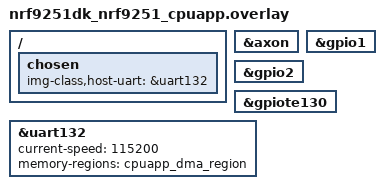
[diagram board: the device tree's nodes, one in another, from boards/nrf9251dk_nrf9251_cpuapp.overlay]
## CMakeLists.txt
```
#
# Copyright (c) 2026 Nordic Semiconductor ASA
#
# SPDX-License-Identifier: LicenseRef-Nordic-5-Clause
#

cmake_minimum_required(VERSION 3.20.0)

find_package(Zephyr REQUIRED HINTS $ENV{ZEPHYR_BASE})
project(wildfire_classification)

target_sources(app PRIVATE
  src/main.c
  src/classification.c
  src/host_input.c
)
```

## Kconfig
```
#
# Copyright (c) 2026 Nordic Semiconductor ASA
#
# SPDX-License-Identifier: LicenseRef-Nordic-5-Clause
#

menu "Wildfire classification application"

config WILDFIRE_SCORE_THRESHOLD
	int "Fire LED threshold, in per mille"
	range 0 1000
	default 500
	help
	  The fire LED is lit when the FIRE class probability reaches this
	  threshold.

config WILDFIRE_RX_BUF_SIZE
	int "Host input UART RX ring buffer size"
	default 4096
	help
	  Bytes buffered between the UART interrupt and the frame parser.

config NRF_AXON_INTERLAYER_BUFFER_SIZE
	int
	default 46080

endmenu

source "Kconfig.zephyr"
```

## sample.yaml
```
sample:
  description: Wildfire classification from host-fed frames
  name: wildfire_classification

common:
  sysbuild: true
  build_only: true
  tags:
    - ci_build
    - sysbuild
    - ci_applications_wildfire_classification
  harness: console
  harness_config:
    type: multi_line
    regex:
      - "waiting for frames from host"

tests:
  applications.wildfire_classification:
    platform_allow:
      - nrf9251dk/nrf9251/cpuapp
    integration_platforms:
      - nrf9251dk/nrf9251/cpuapp
```

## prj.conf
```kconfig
#
# Copyright (c) 2026 Nordic Semiconductor ASA
#
# SPDX-License-Identifier: LicenseRef-Nordic-5-Clause
#

# Logging (results are reported on the console UART)
CONFIG_PRINTK=y
CONFIG_LOG=y
CONFIG_LOG_MODE_IMMEDIATE=y
CONFIG_CBPRINTF_FP_SUPPORT=y

# LEDs
CONFIG_GPIO=y

# Axon NPU (interlayer buffer size is set in Kconfig)
CONFIG_NRF_AXON=y

# Frame input from the host
CONFIG_SERIAL=y
CONFIG_UART_INTERRUPT_DRIVEN=y
CONFIG_RING_BUFFER=y
CONFIG_CRC=y

# Other
CONFIG_ASSERT=y
CONFIG_MAIN_STACK_SIZE=2048
```

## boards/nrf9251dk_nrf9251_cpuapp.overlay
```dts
/*
 * Copyright (c) 2026 Nordic Semiconductor ASA
 * SPDX-License-Identifier: LicenseRef-Nordic-5-Clause
 *
 * nRF9251 DK:
 *   uart133 (P1.5/P1.6) -> J-Link VCOM0: application log and results (zephyr,console)
 *   uart132 (P2.4/P2.5) -> J-Link VCOM1: frame input from the host, RX only
 *
 * Do not use uart120 (P5.2/P5.3) here: those pins are shared with TPIU/coresight on
 * this board (see nrf9251dk_nrf9251-pinctrl.dtsi tpiu_default).
 */

/ {
	chosen {
		img-class,host-uart = &uart132;
	};
};

&axon {
	status = "okay";
};

&gpio1 {
	status = "okay";
};

&gpio2 {
	status = "okay";
};

&gpiote130 {
	status = "okay";
};

&uart132 {
	status = "okay";
	current-speed = <115200>;
	memory-regions = <&cpuapp_dma_region>;
};
```

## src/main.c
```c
/*
 * Copyright (c) 2026 Nordic Semiconductor ASA
 *
 * SPDX-License-Identifier: LicenseRef-Nordic-5-Clause
 */

#include <assert.h>
#include <stdint.h>
#include <string.h>

#include <zephyr/drivers/gpio.h>
#include <zephyr/kernel.h>
#include <zephyr/logging/log.h>

#include <axon/nrf_axon_platform.h>
#include <drivers/axon/nrf_axon_driver.h>
#include <drivers/axon/nrf_axon_nn_infer.h>

#include "classification.h"
#include "host_input.h"

#include "generated/nrf_axon_model_wildfire_.h"

#define AXON_MODEL         model_wildfire
#define MODEL_WIDTH        96
#define MODEL_HEIGHT       96
#define MODEL_OUTPUT_SIZE  NRF_AXON_MODEL_WILDFIRE_PACKED_OUTPUT_SIZE
/* Model input is pixel / 127.5 - 1 (ImageNet MobileNet preprocessing). */
#define INPUT_PIXEL_SCALE  (1.0f / 127.5f)
#define INPUT_PIXEL_OFFSET (-1.0f)
/* Output classes: 0 = NO_FIRE, 1 = FIRE. */
#define FIRE_CLASS_IDX     1

/* downscale_acc is uint16_t: at most 16x16 source pixels of 255 per bin. */
#define MAX_DOWNSCALE 16

LOG_MODULE_REGISTER(main);

static int8_t input_buf[MODEL_WIDTH * MODEL_HEIGHT * 3];
static int8_t output_buf[MODEL_OUTPUT_SIZE];

static uint16_t downscale_acc[3][MODEL_WIDTH * MODEL_HEIGHT];
static uint8_t col_bin_cnt[MODEL_WIDTH];
static uint8_t row_bin_cnt[MODEL_HEIGHT];
static size_t frame_width;
static size_t frame_height;

static const struct gpio_dt_spec led_frame = GPIO_DT_SPEC_GET(DT_ALIAS(led0), gpios);
static const struct gpio_dt_spec led_result = GPIO_DT_SPEC_GET(DT_ALIAS(led1), gpios);

static int led_init(const struct gpio_dt_spec *spec)
{
	int err;

	if (!gpio_is_ready_dt(spec)) {
		LOG_ERR("GPIO %s is not ready", spec->port->name);
		return -ENODEV;
	}

	err = gpio_pin_configure_dt(spec, GPIO_OUTPUT_INACTIVE);
	if (err) {
		LOG_ERR("Failed to configure %s pin %u (err %d)", spec->port->name, spec->pin, err);
		return err;
	}

	return 0;
}

static inline int8_t quantize(const float value, const nrf_axon_nn_compiled_model_input_s *in)
{
	const float scale = (float)in->quant_mult / (float)(1 << in->quant_round);
	const float scaled = value * scale;
	const int32_t quantized =
		(int32_t)(scaled >= 0.0f ? scaled + 0.5f : scaled - 0.5f) + in->quant_zp;

	return (int8_t)__ssat(quantized, 8);
}

static int input_frame_begin(uint16_t width, uint16_t height)
{
	if (width < MODEL_WIDTH || height < MODEL_HEIGHT || width > MAX_DOWNSCALE * MODEL_WIDTH ||
	    height > MAX_DOWNSCALE * MODEL_HEIGHT) {
		return -EINVAL;
	}

	frame_width = width;
	frame_height = height;
	memset(downscale_acc, 0, sizeof(downscale_acc));
	memset(col_bin_cnt, 0, sizeof(col_bin_cnt));
	memset(row_bin_cnt, 0, sizeof(row_bin_cnt));

	for (size_t x = 0; x < width; x++) {
		col_bin_cnt[x * MODEL_WIDTH / width]++;
	}
	for (size_t y = 0; y < height; y++) {
		row_bin_cnt[y * MODEL_HEIGHT / height]++;
	}

	return 0;
}

static void input_frame_pixels(const uint8_t *rgb565_be, size_t pixel_start, size_t pixel_count)
{
	for (size_t p = 0; p < pixel_count; p++) {
		const size_t pixel_idx = pixel_start + p;
		const size_t src_row = pixel_idx / frame_width;
		const size_t src_col = pixel_idx % frame_width;
		const size_t dst = (src_row * MODEL_HEIGHT / frame_height) * MODEL_WIDTH +
				   (src_col * MODEL_WIDTH / frame_width);

		const uint16_t pixel = (uint16_t)rgb565_be[2 * p] << 8 | rgb565_be[2 * p + 1];
		const uint8_t r5 = (pixel >> 11) & 0x1f;
		const uint8_t g6 = (pixel >> 5) & 0x3f;
		const uint8_t b5 = pixel & 0x1f;

		downscale_acc[0][dst] += (r5 << 3) | (r5 >> 2);
		downscale_acc[1][dst] += (g6 << 2) | (g6 >> 4);
		downscale_acc[2][dst] += (b5 << 3) | (b5 >> 2);
	}
}

static void input_frame_end(const nrf_axon_nn_compiled_model_input_s *in)
{
	for (size_t c = 0; c < ARRAY_SIZE(downscale_acc); c++) {
		for (size_t i = 0; i < ARRAY_SIZE(downscale_acc[0]); i++) {
			const uint32_t area =
				row_bin_cnt[i / MODEL_WIDTH] * col_bin_cnt[i % MODEL_WIDTH];
			const uint32_t avg = (downscale_acc[c][i] + (area / 2)) / area;

			input_buf[c * MODEL_WIDTH * MODEL_HEIGHT + i] =
				quantize((float)avg * INPUT_PIXEL_SCALE + INPUT_PIXEL_OFFSET, in);
		}
	}
}

static const struct host_input_handler input_handler = {
	.begin = input_frame_begin,
	.pixels = input_frame_pixels,
};

static int classify(const nrf_axon_nn_compiled_model_s *model)
{
	struct classification_result res;
	nrf_axon_result_e result;
	int err;

	result = nrf_axon_nn_model_infer_sync(model, input_buf, output_buf);
	if (result != NRF_AXON_RESULT_SUCCESS) {
		LOG_ERR("Inference failed (result %d)", result);
		(void)gpio_pin_set_dt(&led_result, 0);
		return -1;
	}

	err = classification_decode(model, output_buf, &res);
	if (err) {
		LOG_ERR("Classification decode failed (err %d)", err);
		(void)gpio_pin_set_dt(&led_result, 0);
		return -1;
	}

	const float top = res.probs[res.class_idx];

	(void)gpio_pin_set_dt(&led_result,
			      (res.probs[FIRE_CLASS_IDX] * 1000.f) >= CONFIG_WILDFIRE_SCORE_THRESHOLD);
	LOG_INF("Class %d: %s (%.1f%%)", res.class_idx, res.label, (double)(top * 100.f));

	return 0;
}

int main(void)
{
	const nrf_axon_nn_compiled_model_s *model = &AXON_MODEL;
	const nrf_axon_nn_compiled_model_input_s *model_input = &model->inputs[0];
	nrf_axon_result_e result;
	int err;

	__ASSERT(model_input->dimensions.width == MODEL_WIDTH &&
		 model_input->dimensions.height == MODEL_HEIGHT &&
		 model_input->dimensions.channel_cnt == 3,
		 "Model input does not match MODEL_WIDTH x MODEL_HEIGHT x 3");

	if (led_init(&led_frame) != 0 || led_init(&led_result) != 0) {
		return -1;
	}

	result = nrf_axon_platform_init();
	if (result != NRF_AXON_RESULT_SUCCESS) {
		LOG_ERR("Axon platform init failed (result %d)", result);
		return -1;
	}

	result = nrf_axon_nn_model_validate(model);
	if (result != NRF_AXON_RESULT_SUCCESS) {
		LOG_ERR("Model validation failed (result %d)", result);
		return -1;
	}

	err = host_input_init();
	if (err) {
		LOG_ERR("Host input init failed (err %d)", err);
		return -1;
	}

	LOG_INF("Model %s (%dx%d) waiting for frames from host", model->model_name, MODEL_WIDTH,
		MODEL_HEIGHT);

	while (true) {
		uint32_t frame_id;
		uint16_t width;
		uint16_t height;

		host_input_receive_frame(&input_handler, &frame_id, &width, &height);
		(void)gpio_pin_toggle_dt(&led_frame);
		input_frame_end(model_input);

		LOG_INF("Frame %u (%ux%u) received", frame_id, width, height);

		if (classify(model) != 0) {
			return -1;
		}
	}

	return 0;
}
```

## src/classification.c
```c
/*
 * Copyright (c) 2026 Nordic Semiconductor ASA
 *
 * SPDX-License-Identifier: LicenseRef-Nordic-5-Clause
 */

#include "classification.h"

#include <errno.h>

int classification_decode(const nrf_axon_nn_compiled_model_s *model, const int8_t *packed_output,
			  struct classification_result *res)
{
	const nrf_axon_nn_model_layer_dimensions_s *dim = &model->outputs[0].dimensions;
	const size_t class_cnt = (size_t)dim->height * dim->width * dim->channel_cnt;
	const int32_t *scores = (const int32_t *)packed_output;
	int32_t top_score;
	int64_t sum = 0;

	if (model->output_cnt != 1 || dim->byte_width != sizeof(int32_t) ||
	    class_cnt > CLASSIFICATION_MAX_CLASSES) {
		return -EINVAL;
	}

	res->class_idx = nrf_axon_nn_get_classification(model, packed_output, &res->label,
							&top_score);
	if (res->class_idx < 0 || (size_t)res->class_idx >= class_cnt) {
		return -EINVAL;
	}
	res->class_cnt = (uint8_t)class_cnt;

	/* Axon softmax emits fixed-point probabilities; normalize by their sum so the
	 * result does not depend on the output Q format.
	 */
	for (size_t i = 0; i < class_cnt; i++) {
		if (scores[i] > 0) {
			sum += scores[i];
		}
	}

	for (size_t i = 0; i < class_cnt; i++) {
		res->probs[i] = (sum > 0 && scores[i] > 0) ? (float)scores[i] / (float)sum : 0.0f;
	}

	return 0;
}
```

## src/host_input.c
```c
/*
 * Copyright (c) 2026 Nordic Semiconductor ASA
 * SPDX-License-Identifier: LicenseRef-Nordic-5-Clause
 */

#include "host_input.h"

#include <errno.h>

#include <zephyr/device.h>
#include <zephyr/drivers/uart.h>
#include <zephyr/kernel.h>
#include <zephyr/logging/log.h>
#include <zephyr/sys/crc.h>
#include <zephyr/sys/ring_buffer.h>
#include <zephyr/sys/util.h>

LOG_MODULE_DECLARE(main);

#if !DT_HAS_CHOSEN(img_class_host_uart)
#error "Host frame input requires img-class,host-uart in devicetree (not the console)"
#endif

#define FRAME_HDR_SIZE  18
#define PAYLOAD_CHUNK   256
#define MAX_FRAME_DIM   512

static const struct device *const input_uart =
	DEVICE_DT_GET(DT_CHOSEN(img_class_host_uart));

RING_BUF_DECLARE(rx_ring, CONFIG_WILDFIRE_RX_BUF_SIZE);
static K_SEM_DEFINE(rx_sem, 0, 1);
static atomic_t rx_dropped;

static void uart_isr(const struct device *dev, void *user_data)
{
	uint8_t buf[64];

	ARG_UNUSED(user_data);

	if (!uart_irq_update(dev)) {
		return;
	}

	while (uart_irq_rx_ready(dev)) {
		const int n = uart_fifo_read(dev, buf, sizeof(buf));

		if (n <= 0) {
			break;
		}

		const uint32_t put = ring_buf_put(&rx_ring, buf, n);

		if (put < (uint32_t)n) {
			atomic_add(&rx_dropped, n - put);
		}
		k_sem_give(&rx_sem);
	}
}

static void rx_read_exact(uint8_t *dst, size_t len)
{
	while (len > 0) {
		const uint32_t n = ring_buf_get(&rx_ring, dst, len);

		if (n == 0) {
			(void)k_sem_take(&rx_sem, K_FOREVER);
			continue;
		}
		dst += n;
		len -= n;
	}
}

static uint16_t le16_get(const uint8_t *src)
{
	return (uint16_t)src[0] | ((uint16_t)src[1] << 8);
}

static uint32_t le32_get(const uint8_t *src)
{
	return (uint32_t)src[0] | ((uint32_t)src[1] << 8) | ((uint32_t)src[2] << 16) |
	       ((uint32_t)src[3] << 24);
}

static void wait_for_magic(uint8_t *hdr)
{
	uint32_t window = 0;

	while (window != HOST_INPUT_MAGIC) {
		uint8_t b;

		rx_read_exact(&b, 1);
		window = (window >> 8) | ((uint32_t)b << 24);
	}

	hdr[0] = (uint8_t)window;
	hdr[1] = (uint8_t)(window >> 8);
	hdr[2] = (uint8_t)(window >> 16);
	hdr[3] = (uint8_t)(window >> 24);
}

int host_input_init(void)
{
	uint8_t discard;

	if (!device_is_ready(input_uart)) {
		LOG_ERR("Host input UART %s not ready", input_uart->name);
		return -ENODEV;
	}

	uart_irq_rx_disable(input_uart);
	uart_irq_tx_disable(input_uart);

	while (uart_fifo_read(input_uart, &discard, 1) > 0) {
	}

	int err = uart_irq_callback_user_data_set(input_uart, uart_isr, NULL);

	if (err) {
		LOG_ERR("Host input UART IRQ setup failed (err %d)", err);
		return err;
	}

	uart_irq_rx_enable(input_uart);
	LOG_INF("Host input on %s (RX only)", input_uart->name);

	return 0;
}

void host_input_receive_frame(const struct host_input_handler *handler, uint32_t *frame_id,
			      uint16_t *width, uint16_t *height)
{
	while (true) {
		uint8_t hdr[FRAME_HDR_SIZE];
		uint8_t chunk[PAYLOAD_CHUNK];
		uint8_t crc_buf[4];
		uint32_t crc = 0U;

		wait_for_magic(hdr);
		rx_read_exact(&hdr[4], sizeof(hdr) - 4);

		const uint16_t w = le16_get(&hdr[6]);
		const uint16_t h = le16_get(&hdr[8]);
		const uint32_t len = le32_get(&hdr[10]);

		if (hdr[4] != HOST_INPUT_VERSION || hdr[5] != HOST_INPUT_TYPE_FRAME ||
		    w == 0 || h == 0 || w > MAX_FRAME_DIM || h > MAX_FRAME_DIM ||
		    len != (uint32_t)w * h * 2U) {
			continue;
		}

		const bool accepted = (handler->begin(w, h) == 0);

		if (!accepted) {
			LOG_WRN("Dropping %ux%u frame (unsupported size)", w, h);
		}

		for (uint32_t off = 0; off < len;) {
			const size_t n = MIN(len - off, sizeof(chunk));

			rx_read_exact(chunk, n);
			crc = crc32_ieee_update(crc, chunk, n);
			if (accepted) {
				handler->pixels(chunk, off / 2U, n / 2U);
			}
			off += n;
		}

		rx_read_exact(crc_buf, sizeof(crc_buf));

		const atomic_val_t dropped = atomic_set(&rx_dropped, 0);

		if (dropped) {
			LOG_WRN("Host input RX overflow, %ld bytes dropped", (long)dropped);
		}

		if (!accepted) {
			continue;
		}

		if (le32_get(crc_buf) != crc) {
			LOG_WRN("Frame %u CRC mismatch, dropped", le32_get(&hdr[14]));
			continue;
		}

		*frame_id = le32_get(&hdr[14]);
		*width = w;
		*height = h;
		return;
	}
}
```

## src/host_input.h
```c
/*
 * Copyright (c) 2026 Nordic Semiconductor ASA
 * SPDX-License-Identifier: LicenseRef-Nordic-5-Clause
 *
 * Receive RGB565 frames from the host over UART.
 *
 * Frame message (little-endian):
 *   [4B magic 0x12345AA5] [1B version] [1B type=0x01] [2B width] [2B height]
 *   [4B payload_len] [4B frame_id] [payload: RGB565 big-endian] [4B crc32(payload)]
 */

#pragma once

#include <stddef.h>
#include <stdint.h>

#define HOST_INPUT_MAGIC      0x12345AA5U
#define HOST_INPUT_VERSION    1
#define HOST_INPUT_TYPE_FRAME 0x01

struct host_input_handler {
	/** Called when a frame header arrives. Return non-zero to reject the frame. */
	int (*begin)(uint16_t width, uint16_t height);
	/** Called with consecutive RGB565 big-endian pixels of the current frame. */
	void (*pixels)(const uint8_t *rgb565_be, size_t pixel_start, size_t pixel_count);
};

int host_input_init(void);

/**
 * @brief Block until one complete frame with a valid CRC has been received.
 *
 * Frames that are rejected by @p handler->begin or fail the CRC check are
 * dropped and reception continues.
 *
 * @param handler Frame callbacks.
 * @param[out] frame_id Host frame ID of the received frame.
 * @param[out] width Frame width.
 * @param[out] height Frame height.
 */
void host_input_receive_frame(const struct host_input_handler *handler, uint32_t *frame_id,
			      uint16_t *width, uint16_t *height);
```
